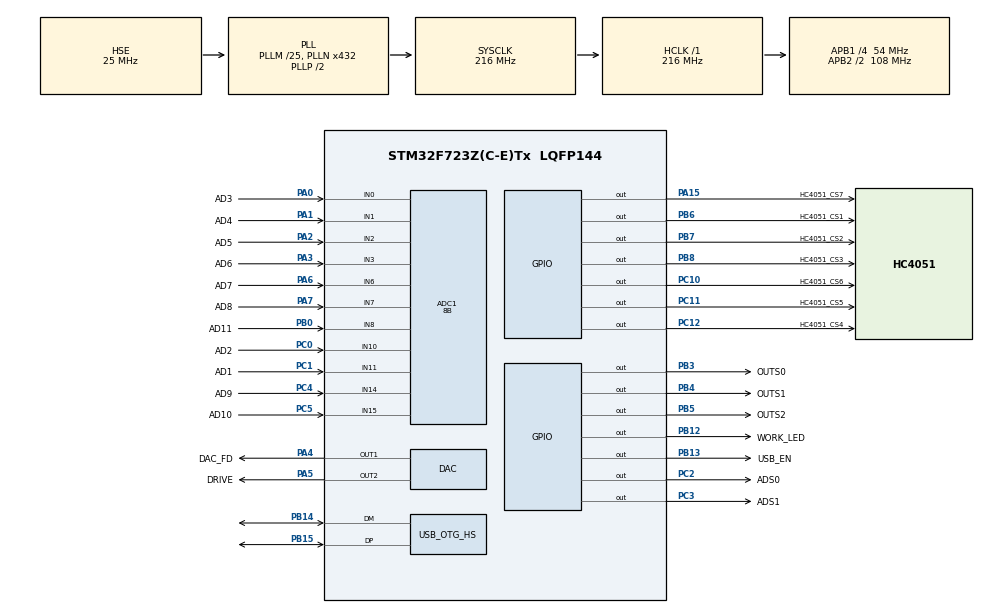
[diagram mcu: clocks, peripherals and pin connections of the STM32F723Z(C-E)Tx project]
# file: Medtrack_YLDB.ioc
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ADC1.Channel-0\#ChannelRegularConversion=ADC_CHANNEL_11
ADC1.Channel-1\#ChannelRegularConversion=ADC_CHANNEL_10
ADC1.Channel-10\#ChannelRegularConversion=ADC_CHANNEL_8
ADC1.Channel-2\#ChannelRegularConversion=ADC_CHANNEL_0
ADC1.Channel-3\#ChannelRegularConversion=ADC_CHANNEL_1
ADC1.Channel-4\#ChannelRegularConversion=ADC_CHANNEL_2
ADC1.Channel-5\#ChannelRegularConversion=ADC_CHANNEL_3
ADC1.Channel-6\#ChannelRegularConversion=ADC_CHANNEL_6
ADC1.Channel-7\#ChannelRegularConversion=ADC_CHANNEL_7
ADC1.Channel-8\#ChannelRegularConversion=ADC_CHANNEL_14
ADC1.Channel-9\#ChannelRegularConversion=ADC_CHANNEL_15
ADC1.ContinuousConvMode=DISABLE
ADC1.DMAContinuousRequests=ENABLE
ADC1.EOCSelection=ADC_EOC_SEQ_CONV
ADC1.InjNumberOfConversion=0
ADC1.NbrOfConversion=11
ADC1.NbrOfConversionFlag=1
ADC1.Rank-0\#ChannelRegularConversion=1
ADC1.Rank-1\#ChannelRegularConversion=2
ADC1.Rank-10\#ChannelRegularConversion=11
ADC1.Rank-2\#ChannelRegularConversion=3
ADC1.Rank-3\#ChannelRegularConversion=4
ADC1.Rank-4\#ChannelRegularConversion=5
ADC1.Rank-5\#ChannelRegularConversion=6
ADC1.Rank-6\#ChannelRegularConversion=7
ADC1.Rank-7\#ChannelRegularConversion=8
ADC1.Rank-8\#ChannelRegularConversion=9
ADC1.Rank-9\#ChannelRegularConversion=10
ADC1.Resolution=ADC_RESOLUTION_8B
ADC1.SamplingTime-0\#ChannelRegularConversion=ADC_SAMPLETIME_3CYCLES
ADC1.SamplingTime-1\#ChannelRegularConversion=ADC_SAMPLETIME_3CYCLES
ADC1.SamplingTime-10\#ChannelRegularConversion=ADC_SAMPLETIME_3CYCLES
ADC1.SamplingTime-2\#ChannelRegularConversion=ADC_SAMPLETIME_3CYCLES
ADC1.SamplingTime-3\#ChannelRegularConversion=ADC_SAMPLETIME_3CYCLES
ADC1.SamplingTime-4\#ChannelRegularConversion=ADC_SAMPLETIME_3CYCLES
ADC1.SamplingTime-5\#ChannelRegularConversion=ADC_SAMPLETIME_3CYCLES
ADC1.SamplingTime-6\#ChannelRegularConversion=ADC_SAMPLETIME_3CYCLES
ADC1.SamplingTime-7\#ChannelRegularConversion=ADC_SAMPLETIME_3CYCLES
ADC1.SamplingTime-8\#ChannelRegularConversion=ADC_SAMPLETIME_3CYCLES
ADC1.SamplingTime-9\#ChannelRegularConversion=ADC_SAMPLETIME_3CYCLES
ADC1.ScanConvMode=ADC_SCAN_ENABLE
ADC1.master=1
DAC.DAC_OutputBuffer=DAC_OUTPUTBUFFER_DISABLE
DAC.DAC_OutputBuffer2=DAC_OUTPUTBUFFER_DISABLE
Dma.ADC1.0.Direction=DMA_PERIPH_TO_MEMORY
Dma.ADC1.0.FIFOMode=DMA_FIFOMODE_DISABLE
Dma.ADC1.0.Instance=DMA2_Stream0
Dma.ADC1.0.MemDataAlignment=DMA_MDATAALIGN_BYTE
Dma.ADC1.0.MemInc=DMA_MINC_ENABLE
Dma.ADC1.0.Mode=DMA_NORMAL
Dma.ADC1.0.PeriphDataAlignment=DMA_PDATAALIGN_BYTE
Dma.ADC1.0.PeriphInc=DMA_PINC_DISABLE
Dma.ADC1.0.Priority=DMA_PRIORITY_LOW
Dma.Request0=ADC1
Mcu.Family=STM32F7
Mcu.Name=STM32F723Z(C-E)Tx
Mcu.Package=LQFP144
NVIC.DMA2_Stream0_IRQn=true\:0\:0\:false\:false\:true\:false\:true\:true
NVIC.OTG_HS_IRQn=true\:0\:0\:false\:false\:true\:false\:true\:true
NVIC.PriorityGroup=NVIC_PRIORITYGROUP_4
NVIC.TIM2_IRQn=true\:0\:0\:false\:false\:true\:true\:true\:true
PA0-WKUP.GPIO_Label=AD3
PA0-WKUP.Signal=ADCx_IN0
PA1.GPIO_Label=AD4
PA1.Signal=ADCx_IN1
PA13.Mode=Serial_Wire
PA13.Signal=SYS_JTMS-SWDIO
PA14.Mode=Serial_Wire
PA14.Signal=SYS_JTCK-SWCLK
PA15.GPIO_Label=HC4051_CS7
PA15.GPIO_PuPd=GPIO_PULLUP
PA15.GPIO_Speed=GPIO_SPEED_FREQ_VERY_HIGH
PA15.PinState=GPIO_PIN_SET
PA15.Signal=GPIO_Output
PA2.GPIO_Label=AD5
PA2.Signal=ADCx_IN2
PA3.GPIO_Label=AD6
PA3.Signal=ADCx_IN3
PA4.GPIO_Label=DAC_FD
PA4.Signal=COMP_DAC1_group
PA5.GPIO_Label=DRIVE
PA5.Signal=COMP_DAC2_group
PA6.GPIO_Label=AD7
PA6.Signal=ADCx_IN6
PA7.GPIO_Label=AD8
PA7.Signal=ADCx_IN7
PB0.GPIO_Label=AD11
PB0.Signal=ADCx_IN8
PB12.GPIO_Label=WORK_LED
PB12.GPIO_PuPd=GPIO_PULLUP
PB12.GPIO_Speed=GPIO_SPEED_FREQ_HIGH
PB12.PinState=GPIO_PIN_SET
PB12.Signal=GPIO_Output
PB13.GPIO_Label=USB_EN
PB13.GPIO_PuPd=GPIO_PULLDOWN
PB13.GPIO_Speed=GPIO_SPEED_FREQ_LOW
PB13.Signal=GPIO_Output
PB14.Mode=Internal_Phy_Device
PB14.Signal=USB_OTG_HS_DM
PB15.GPIO_PuPd=GPIO_NOPULL
PB15.Mode=Internal_Phy_Device
PB15.Signal=USB_OTG_HS_DP
PB3.GPIO_Label=OUTS0
PB3.GPIO_PuPd=GPIO_PULLUP
PB3.GPIO_Speed=GPIO_SPEED_FREQ_VERY_HIGH
PB3.PinState=GPIO_PIN_RESET
PB3.Signal=GPIO_Output
PB4.GPIO_Label=OUTS1
PB4.GPIO_PuPd=GPIO_PULLUP
PB4.GPIO_Speed=GPIO_SPEED_FREQ_VERY_HIGH
PB4.Signal=GPIO_Output
PB5.GPIO_Label=OUTS2
PB5.GPIO_PuPd=GPIO_PULLDOWN
PB5.GPIO_Speed=GPIO_SPEED_FREQ_VERY_HIGH
PB5.Signal=GPIO_Output
PB6.GPIO_FM6=SYSCFG_PMC_I2C_PB6_FMP
PB6.GPIO_Label=HC4051_CS1
PB6.GPIO_PuPd=GPIO_PULLUP
PB6.GPIO_Speed=GPIO_SPEED_FREQ_VERY_HIGH
PB6.PinState=GPIO_PIN_SET
PB6.Signal=GPIO_Output
PB7.GPIO_FM7=SYSCFG_PMC_I2C_PB7_FMP
PB7.GPIO_Label=HC4051_CS2
PB7.GPIO_PuPd=GPIO_PULLUP
PB7.GPIO_Speed=GPIO_SPEED_FREQ_VERY_HIGH
PB7.PinState=GPIO_PIN_SET
PB7.Signal=GPIO_Output
PB8.GPIO_FM8=SYSCFG_PMC_I2C_PB8_FMP
PB8.GPIO_Label=HC4051_CS3
PB8.GPIO_PuPd=GPIO_PULLUP
PB8.GPIO_Speed=GPIO_SPEED_FREQ_VERY_HIGH
PB8.PinState=GPIO_PIN_SET
PB8.Signal=GPIO_Output
PC0.GPIO_Label=AD2
PC0.Signal=ADCx_IN10
PC1.GPIO_Label=AD1
PC1.Signal=ADCx_IN11
PC10.GPIO_Label=HC4051_CS6
PC10.GPIO_PuPd=GPIO_PULLUP
PC10.GPIO_Speed=GPIO_SPEED_FREQ_VERY_HIGH
PC10.PinState=GPIO_PIN_SET
PC10.Signal=GPIO_Output
PC11.GPIO_Label=HC4051_CS5
PC11.GPIO_PuPd=GPIO_PULLUP
PC11.GPIO_Speed=GPIO_SPEED_FREQ_VERY_HIGH
PC11.PinState=GPIO_PIN_SET
PC11.Signal=GPIO_Output
PC12.GPIO_Label=HC4051_CS4
PC12.GPIO_PuPd=GPIO_PULLUP
PC12.GPIO_Speed=GPIO_SPEED_FREQ_VERY_HIGH
PC12.PinState=GPIO_PIN_SET
PC12.Signal=GPIO_Output
PC2.GPIO_Label=ADS0
PC2.GPIO_PuPd=GPIO_PULLDOWN
PC2.GPIO_Speed=GPIO_SPEED_FREQ_VERY_HIGH
PC2.Signal=GPIO_Output
PC3.GPIO_Label=ADS1
PC3.GPIO_PuPd=GPIO_PULLDOWN
PC3.GPIO_Speed=GPIO_SPEED_FREQ_VERY_HIGH
PC3.Signal=GPIO_Output
PC4.GPIO_Label=AD9
PC4.Signal=ADCx_IN14
PC5.GPIO_Label=AD10
PC5.Signal=ADCx_IN15
PH0-OSC_IN.Mode=HSE-External-Oscillator
PH0-OSC_IN.Signal=RCC_OSC_IN
PH1-OSC_OUT.Mode=HSE-External-Oscillator
PH1-OSC_OUT.Signal=RCC_OSC_OUT
ProjectManager.HeapSize=0x2000
ProjectManager.StackSize=0x4000
ProjectManager.TargetToolchain=MDK-ARM V5.32
RCC.AHBFreq_Value=216000000
RCC.APB1CLKDivider=RCC_HCLK_DIV4
RCC.APB1Freq_Value=54000000
RCC.APB1TimFreq_Value=216000000
RCC.APB2CLKDivider=RCC_HCLK_DIV2
RCC.APB2Freq_Value=108000000
RCC.APB2TimFreq_Value=216000000
RCC.CortexFreq_Value=216000000
RCC.HCLKFreq_Value=216000000
RCC.HSE_VALUE=25000000
RCC.HSI_VALUE=16000000
RCC.LSE_VALUE=32768
RCC.PLLM=25
RCC.PLLN=432
RCC.PLLQ=9
RCC.RCC_MCO1Source=RCC_MCO1SOURCE_PLLCLK
RCC.RCC_TIM_PRescaler_Selection=RCC_TIMPRES_ACTIVATED
RCC.SYSCLKFreq_VALUE=216000000
RCC.SYSCLKSource=RCC_SYSCLKSOURCE_PLLCLK
RCC.USBFreq_Value=48000000
RCC.VCOOutputFreq_Value=432000000
REXTPHYHS.Mode=Internal_Phy_Device
REXTPHYHS.Signal=USB_OTG_HS_REXTPHYHS
SH.ADCx_IN0.0=ADC1_IN0,IN0
SH.ADCx_IN1.0=ADC1_IN1,IN1
SH.ADCx_IN10.0=ADC1_IN10,IN10
SH.ADCx_IN11.0=ADC1_IN11,IN11
SH.ADCx_IN14.0=ADC1_IN14,IN14
SH.ADCx_IN15.0=ADC1_IN15,IN15
SH.ADCx_IN2.0=ADC1_IN2,IN2
SH.ADCx_IN3.0=ADC1_IN3,IN3
SH.ADCx_IN6.0=ADC1_IN6,IN6
SH.ADCx_IN7.0=ADC1_IN7,IN7
SH.ADCx_IN8.0=ADC1_IN8,IN8
SH.COMP_DAC1_group.0=DAC_OUT1,DAC_OUT1
SH.COMP_DAC2_group.0=DAC_OUT2,DAC_OUT2
TIM2.AutoReloadPreload=TIM_AUTORELOAD_PRELOAD_ENABLE
TIM2.ClockDivision=TIM_CLOCKDIVISION_DIV2
TIM2.Period=2159
TIM2.Prescaler=999
USB_DEVICE.APP_RX_DATA_SIZE-CDC_HS=2048
USB_DEVICE.APP_TX_DATA_SIZE-CDC_HS=2048
USB_DEVICE.CLASS_NAME_HS=CDC
USB_DEVICE.USBD_LPM_ENABLED-CDC_HS=0
USB_DEVICE.USBD_MAX_NUM_CONFIGURATION-CDC_HS=1
USB_DEVICE.USBD_MAX_NUM_INTERFACES-CDC_HS=1
USB_DEVICE.USBD_MAX_STR_DESC_SIZ-CDC_HS=1536
USB_DEVICE.USBD_SELF_POWERED-CDC_HS=0
USB_DEVICE.VirtualMode-CDC_HS=Cdc
USB_DEVICE.VirtualModeHS=Cdc_HS
USB_OTG_HS.Sof_enable-Internal_Phy_Device=DISABLE
USB_OTG_HS.VirtualMode=Int_Phy_Device
USB_OTG_HS.dma_enable=DISABLE
USB_OTG_HS.speed=USB_OTG_SPEED_HIGH
USB_OTG_HS.use_dedicated_ep1=DISABLE
VP_TIM2_VS_ClockSourceINT.Mode=Internal
VP_USB_DEVICE_VS_USB_DEVICE_CDC_HS.Mode=CDC_HS
board=custom

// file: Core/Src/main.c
/* USER CODE BEGIN Header */
/**
  ******************************************************************************
  * @file           : main.c
  * @brief          : Main program body
  ******************************************************************************
  * @attention
  *
  * <h2><center>&copy; Copyright (c) 2023 STMicroelectronics.
  * All rights reserved.</center></h2>
  *
  * This software component is licensed by ST under BSD 3-Clause license,
  * the "License"; You may not use this file except in compliance with the
  * License. You may obtain a copy of the License at:
  *                        opensource.org/licenses/BSD-3-Clause
  *
  ******************************************************************************
  */
/* USER CODE END Header */
#include "main.h"
#include "adc.h"
#include "dac.h"
#include "dma.h"
#include "tim.h"
#include "usb_device.h"
#include "gpio.h"

/* USER CODE BEGIN Includes */
#include "system.h"

/* USER CODE END Includes */

void SystemClock_Config(void);
void PeriphCommonClock_Config(void);

int main(void)
{

  /* MCU Configuration--------------------------------------------------------*/

  /* Reset of all peripherals, Initializes the Flash interface and the Systick. */
  HAL_Init();

  /* Configure the system clock */
  SystemClock_Config();

/* Configure the peripherals common clocks */
  PeriphCommonClock_Config();

  /* Initialize all configured peripherals */
  MX_GPIO_Init();
  MX_DMA_Init();
  MX_USB_DEVICE_Init();
  MX_ADC1_Init();
  MX_DAC_Init();
  MX_TIM2_Init();
  /* USER CODE BEGIN 2 */
  system_init();
  /* USER CODE END 2 */

  /* Infinite loop */
  /* USER CODE BEGIN WHILE */
  while (1)
  {
    system_run();
    /* USER CODE END WHILE */

  }
}

void SystemClock_Config(void)
{
  RCC_OscInitTypeDef RCC_OscInitStruct = {0};
  RCC_ClkInitTypeDef RCC_ClkInitStruct = {0};

  /** Configure the main internal regulator output voltage
  */
  __HAL_RCC_PWR_CLK_ENABLE();
  __HAL_PWR_VOLTAGESCALING_CONFIG(PWR_REGULATOR_VOLTAGE_SCALE1);

  /** Initializes the RCC Oscillators according to the specified parameters
  * in the RCC_OscInitTypeDef structure.
  */
  RCC_OscInitStruct.OscillatorType = RCC_OSCILLATORTYPE_HSE;
  RCC_OscInitStruct.HSEState = RCC_HSE_ON;
  RCC_OscInitStruct.PLL.PLLState = RCC_PLL_ON;
  RCC_OscInitStruct.PLL.PLLSource = RCC_PLLSOURCE_HSE;
  RCC_OscInitStruct.PLL.PLLM = 25;
  RCC_OscInitStruct.PLL.PLLN = 432;
  RCC_OscInitStruct.PLL.PLLP = RCC_PLLP_DIV2;
  RCC_OscInitStruct.PLL.PLLQ = 9;
  if (HAL_RCC_OscConfig(&RCC_OscInitStruct) != HAL_OK)
  {
    Error_Handler();
  }

  /** Activate the Over-Drive mode
  */
  if (HAL_PWREx_EnableOverDrive() != HAL_OK)
  {
    Error_Handler();
  }

  /** Initializes the CPU, AHB and APB buses clocks
  */
  RCC_ClkInitStruct.ClockType = RCC_CLOCKTYPE_HCLK|RCC_CLOCKTYPE_SYSCLK
                              |RCC_CLOCKTYPE_PCLK1|RCC_CLOCKTYPE_PCLK2;
  RCC_ClkInitStruct.SYSCLKSource = RCC_SYSCLKSOURCE_PLLCLK;
  RCC_ClkInitStruct.AHBCLKDivider = RCC_SYSCLK_DIV1;
  RCC_ClkInitStruct.APB1CLKDivider = RCC_HCLK_DIV4;
  RCC_ClkInitStruct.APB2CLKDivider = RCC_HCLK_DIV2;

  if (HAL_RCC_ClockConfig(&RCC_ClkInitStruct, FLASH_LATENCY_7) != HAL_OK)
  {
    Error_Handler();
  }
}

void PeriphCommonClock_Config(void)
{
  RCC_PeriphCLKInitTypeDef PeriphClkInitStruct = {0};

  /** Initializes the peripherals clock
  */
  PeriphClkInitStruct.PeriphClockSelection = RCC_PERIPHCLK_TIM;
  PeriphClkInitStruct.TIMPresSelection = RCC_TIMPRES_ACTIVATED;

  if (HAL_RCCEx_PeriphCLKConfig(&PeriphClkInitStruct) != HAL_OK)
  {
    Error_Handler();
  }
}

void Error_Handler(void)
{
  __disable_irq();
  while (1)
  {
  }
}
